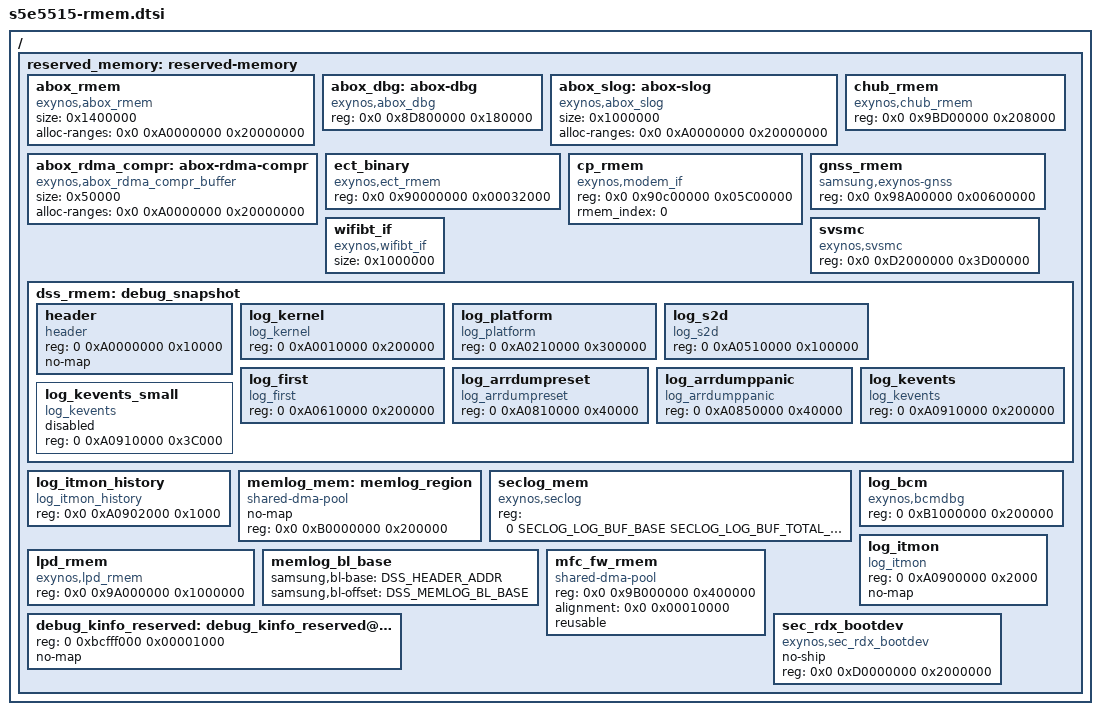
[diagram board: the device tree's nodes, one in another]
/*
 * SAMSUNG EXYNOS device tree source for reserved-memory
 *
 * Copyright (c) 2018 Samsung Electronics Co., Ltd.
 *		http://www.samsung.com
 *
 * This program is free software; you can redistribute it and/or modify
 * it under the terms of the GNU General Public License version 2 as
 * published by the Free Software Foundation.
 */

#include <dt-bindings/soc/samsung/exynos/debug-snapshot-def.h>
#include <dt-bindings/soc/samsung/exynos5515-seclog.h>

/ {
	reserved_memory: reserved-memory {
		#address-cells = <2>;
		#size-cells = <1>;
		ranges;

		abox_rmem: abox_rmem {
			compatible = "exynos,abox_rmem";
			size = <0x1400000>;
			alloc-ranges = <0x0 0xA0000000 0x20000000>;
		};

		abox_dbg: abox-dbg {
			compatible = "exynos,abox_dbg";
			reg = <0x0 0x8D800000 0x180000>;
		};

		abox_slog: abox-slog {
			compatible = "exynos,abox_slog";
			size = <0x1000000>;
			alloc-ranges = <0x0 0xA0000000 0x20000000>;
		};

		abox_rdma_compr: abox-rdma-compr {
			compatible = "exynos,abox_rdma_compr_buffer";
			size = <0x50000>;
			alloc-ranges = <0x0 0xA0000000 0x20000000>;
		};

		ect_binary: ect_binary {
			compatible = "exynos,ect_rmem";
			reg = <0x0 0x90000000 0x00032000>;
		};

		chub_rmem: chub_rmem {
			compatible = "exynos,chub_rmem";
			/* To dump SHUB SRAM out upon shub firmware crash */
			reg = <0x0 0x9BD00000 0x208000>;
		};

		cp_rmem: cp_rmem {
			compatible = "exynos,modem_if";
			reg = <0x0 0x90c00000 0x05C00000>;
			rmem_index = <0>;
		};

		gnss_rmem: gnss_rmem {
			compatible = "samsung,exynos-gnss";
			reg = <0x0 0x98A00000 0x00600000>;
		};

		wifibt_if: wifibt_if{
			compatible = "exynos,wifibt_if";
			size = <0x1000000>; /* 16MB */
		};

		svsmc {
			compatible = "exynos,svsmc";
			reg = <0x0 0xD2000000 0x3D00000>;
		};

		dss_rmem: debug_snapshot {
			#address-cells = <2>;
			#size-cells = <1>;
			header: header {
				compatible = "header";
				reg = <0 0xA0000000 0x10000>;
				no-map;
			};
			log_kernel: log_kernel {
				compatible = "log_kernel";
				reg = <0 0xA0010000 0x200000>;
			};
			log_platform: log_platform {
				compatible = "log_platform";
				reg = <0 0xA0210000 0x300000>;
			};
			log_s2d: log_s2d {
				compatible = "log_s2d";
				reg = <0 0xA0510000 0x100000>;
			};
			log_first: log_first {
				compatible = "log_first";
				reg = <0 0xA0610000 0x200000>;
			};
			log_arrdumpreset: log_arrdumpreset {
				compatible = "log_arrdumpreset";
				reg = <0 0xA0810000 0x40000>;
			};
			log_arrdumppanic: log_arrdumppanic {
				compatible = "log_arrdumppanic";
				reg = <0 0xA0850000 0x40000>;
			};
			log_kevents: log_kevents {
				compatible = "log_kevents";
				reg = <0 0xA0910000 0x200000>;
			};
			log_kevents_small: log_kevents_small {
				compatible = "log_kevents";
				reg = <0 0xA0910000 0x3C000>;
				status = "no";
			};
		};

		log_itmon_history: log_itmon_history {
			compatible = "log_itmon_history";
			reg = <0x0 0xA0902000 0x1000>;
		};

		memlog_mem: memlog_region {
			compatible = "shared-dma-pool";
			no-map;
			reg = <0x0 0xB0000000 0x200000>;
		};

		seclog_mem: seclog_mem {
			compatible = "exynos,seclog";
			reg = <0 SECLOG_LOG_BUF_BASE SECLOG_LOG_BUF_TOTAL_SIZE>;
		};

		lpd_rmem: lpd_rmem {
			compatible = "exynos,lpd_rmem";
			reg = <0x0 0x9A000000 0x1000000>;
		};

		log_bcm: log_bcm {
			compatible = "exynos,bcmdbg";
			reg = <0 0xB1000000 0x200000>;
		};

		memlog_bl_base: memlog_bl_base {
			samsung,bl-base = <DSS_HEADER_ADDR>;
			samsung,bl-offset = <DSS_MEMLOG_BL_BASE>;
		};

		log_itmon: log_itmon {
			compatible = "log_itmon";
			reg = <0 0xA0900000 0x2000>;
			no-map;
		};

		debug_kinfo_reserved: debug_kinfo_reserved@bcfff000 {
			reg = <0 0xbcfff000 0x00001000>;
			no-map;
		};

		mfc_fw_rmem: mfc_fw_rmem {
			compatible = "shared-dma-pool";
			reg = <0x0 0x9B000000 0x400000>;
			alignment = <0x0 0x00010000>;
			reusable;
		};


		sec_rdx_bootdev {
			compatible = "exynos,sec_rdx_bootdev";
			no-ship;
			reg = <0x0 0xD0000000 0x2000000>;
		};
	};
};
